# ATSAME54N20A device description
Architecture: CORTEX-M4; Family: SAMD; Series: SAME54
Registers are 32-bit, read-write, reset 0x0 unless marked. A register's access mark holds for its fields unless they carry their own. Offsets are from the block's base; [hi:lo] are bit positions; {n}, {i} and the like mark numbered series.

## PAC — Peripheral Access Controller
Instances: PAC 0x40000000
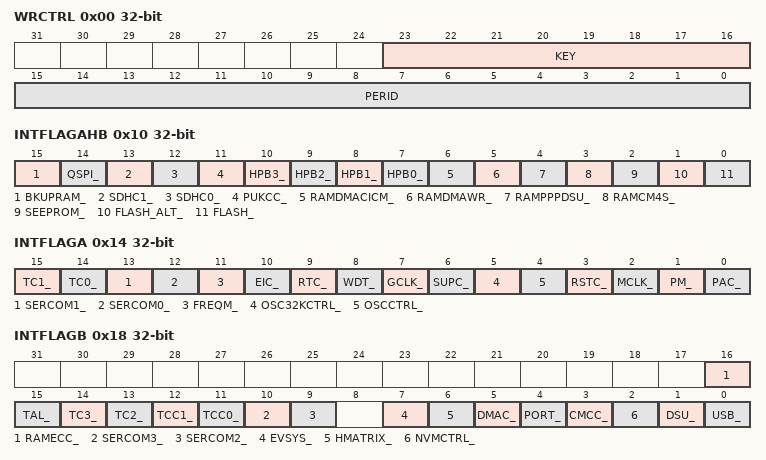
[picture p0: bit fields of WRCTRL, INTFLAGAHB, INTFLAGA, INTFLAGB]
0x00 WRCTRL — Write control
  [23:16] KEY — Peripheral access control key
    0=OFF (No action); 1=CLR (Clear protection); 2=SET (Set protection); 3=SETLCK (Set and lock protection)
  [15:0] PERID — Peripheral identifier
0x04 EVCTRL 8-bit — Event control
  [0] ERREO — Peripheral acess error event output
0x08 INTENCLR 8-bit (atomic clear) — Interrupt enable clear
  [0] ERR — Peripheral access error interrupt disable
0x09 INTENSET 8-bit (atomic set) — Interrupt enable set
  [0] ERR — Peripheral access error interrupt enable
0x10 INTFLAGAHB (atomic clear) — Bridge interrupt flag status
  [15] BKUPRAM_, [14] QSPI_, [13] SDHC1_, [12] SDHC0_, [11] PUKCC_, [n+7] HPB{n}_ (n=0..3), [6] RAMDMACICM_, [5] RAMDMAWR_, [4] RAMPPPDSU_, [3] RAMCM4S_, [2] SEEPROM_, [1] FLASH_ALT_, [0] FLASH_
0x14 INTFLAGA (atomic clear) — Peripheral interrupt flag status - Bridge A
  [15] TC1_, [14] TC0_, [13] SERCOM1_, [12] SERCOM0_, [11] FREQM_, [10] EIC_, [9] RTC_, [8] WDT_, [7] GCLK_, [6] SUPC_, [5] OSC32KCTRL_, [4] OSCCTRL_, [3] RSTC_, [2] MCLK_, [1] PM_, [0] PAC_
0x18 INTFLAGB (atomic clear) — Peripheral interrupt flag status - Bridge B
  [16] RAMECC_, [15] TAL_, [14] TC3_, [13] TC2_, [12] TCC1_, [11] TCC0_, [10] SERCOM3_, [9] SERCOM2_, [7] EVSYS_, [6] HMATRIX_, [5] DMAC_, [4] PORT_, [3] CMCC_, [2] NVMCTRL_, [1] DSU_, [0] USB_
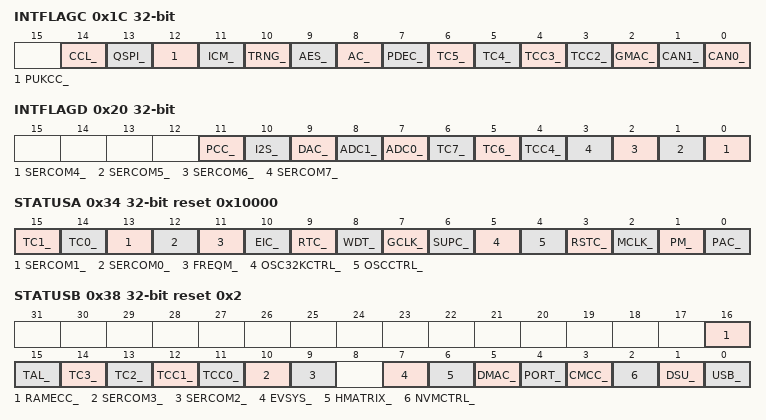
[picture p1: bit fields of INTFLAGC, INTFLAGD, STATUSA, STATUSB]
0x1C INTFLAGC (atomic clear) — Peripheral interrupt flag status - Bridge C
  [14] CCL_, [13] QSPI_, [12] PUKCC_, [11] ICM_, [10] TRNG_, [9] AES_, [8] AC_, [7] PDEC_, [6] TC5_, [5] TC4_, [4] TCC3_, [3] TCC2_, [2] GMAC_, [1] CAN1_, [0] CAN0_
0x20 INTFLAGD (atomic clear) — Peripheral interrupt flag status - Bridge D
  [11] PCC_, [10] I2S_, [9] DAC_, [8] ADC1_, [7] ADC0_, [6] TC7_, [5] TC6_, [4] TCC4_, [n-4] SERCOM{n}_ (n=4..7)
0x34 STATUSA ro reset 0x10000 — Peripheral write protection status - Bridge A
  [15] TC1_ — TC1 APB Protect Enable
  [14] TC0_ — TC0 APB Protect Enable
  [13] SERCOM1_ — SERCOM1 APB Protect Enable
  [12] SERCOM0_ — SERCOM0 APB Protect Enable
  [11] FREQM_ — FREQM APB Protect Enable
  [10] EIC_ — EIC APB Protect Enable
  [9] RTC_ — RTC APB Protect Enable
  [8] WDT_ — WDT APB Protect Enable
  [7] GCLK_ — GCLK APB Protect Enable
  [6] SUPC_ — SUPC APB Protect Enable
  [5] OSC32KCTRL_ — OSC32KCTRL APB Protect Enable
  [4] OSCCTRL_ — OSCCTRL APB Protect Enable
  [3] RSTC_ — RSTC APB Protect Enable
  [2] MCLK_ — MCLK APB Protect Enable
  [1] PM_ — PM APB Protect Enable
  [0] PAC_ — PAC APB Protect Enable
0x38 STATUSB ro reset 0x2 — Peripheral write protection status - Bridge B
  [16] RAMECC_ — RAMECC APB Protect Enable
  [15] TAL_ — TAL APB Protect Enable
  [14] TC3_ — TC3 APB Protect Enable
  [13] TC2_ — TC2 APB Protect Enable
  [12] TCC1_ — TCC1 APB Protect Enable
  [11] TCC0_ — TCC0 APB Protect Enable
  [10] SERCOM3_ — SERCOM3 APB Protect Enable
  [9] SERCOM2_ — SERCOM2 APB Protect Enable
  [7] EVSYS_ — EVSYS APB Protect Enable
  [6] HMATRIX_ — HMATRIX APB Protect Enable
  [5] DMAC_ — DMAC APB Protect Enable
  [4] PORT_ — PORT APB Protect Enable
  [3] CMCC_ — CMCC APB Protect Enable
  [2] NVMCTRL_ — NVMCTRL APB Protect Enable
  [1] DSU_ — DSU APB Protect Enable
  [0] USB_ — USB APB Protect Enable
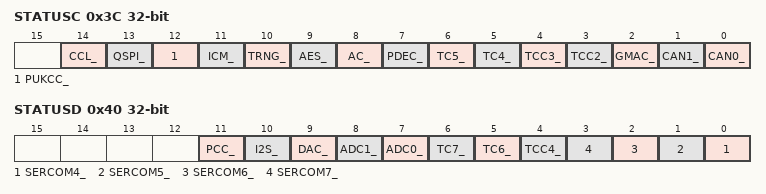
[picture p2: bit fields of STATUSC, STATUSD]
0x3C STATUSC ro — Peripheral write protection status - Bridge C
  [14] CCL_ — CCL APB Protect Enable
  [13] QSPI_ — QSPI APB Protect Enable
  [12] PUKCC_ — PUKCC APB Protect Enable
  [11] ICM_ — ICM APB Protect Enable
  [10] TRNG_ — TRNG APB Protect Enable
  [9] AES_ — AES APB Protect Enable
  [8] AC_ — AC APB Protect Enable
  [7] PDEC_ — PDEC APB Protect Enable
  [6] TC5_ — TC5 APB Protect Enable
  [5] TC4_ — TC4 APB Protect Enable
  [4] TCC3_ — TCC3 APB Protect Enable
  [3] TCC2_ — TCC2 APB Protect Enable
  [2] GMAC_ — GMAC APB Protect Enable
  [1] CAN1_ — CAN1 APB Protect Enable
  [0] CAN0_ — CAN0 APB Protect Enable
0x40 STATUSD ro — Peripheral write protection status - Bridge D
  [11] PCC_ — PCC APB Protect Enable
  [10] I2S_ — I2S APB Protect Enable
  [9] DAC_ — DAC APB Protect Enable
  [8] ADC1_ — ADC1 APB Protect Enable
  [7] ADC0_ — ADC0 APB Protect Enable
  [6] TC7_ — TC7 APB Protect Enable
  [5] TC6_ — TC6 APB Protect Enable
  [4] TCC4_ — TCC4 APB Protect Enable
  [n-4] SERCOM{n}_ (n=4..7) — SERCOM{n} APB Protect Enable

## Notices in the file
Copyright (c) 2017 Atmel Corporation,
a wholly owned subsidiary of Microchip Technology Inc.
Licensed under the Apache License, Version 2.0 (the "License");
you may not use this file except in compliance with the License.
You may obtain a copy of the Licence at
http://www.apache.org/licenses/LICENSE-2.0
Unless required by applicable law or agreed to in writing, software
distributed under the License is distributed on an "AS IS" BASIS,
WITHOUT WARRANTIES OR CONDITIONS OF ANY KIND, either express or implied.
See the License for the specific language governing permissions and
limitations under the License.
